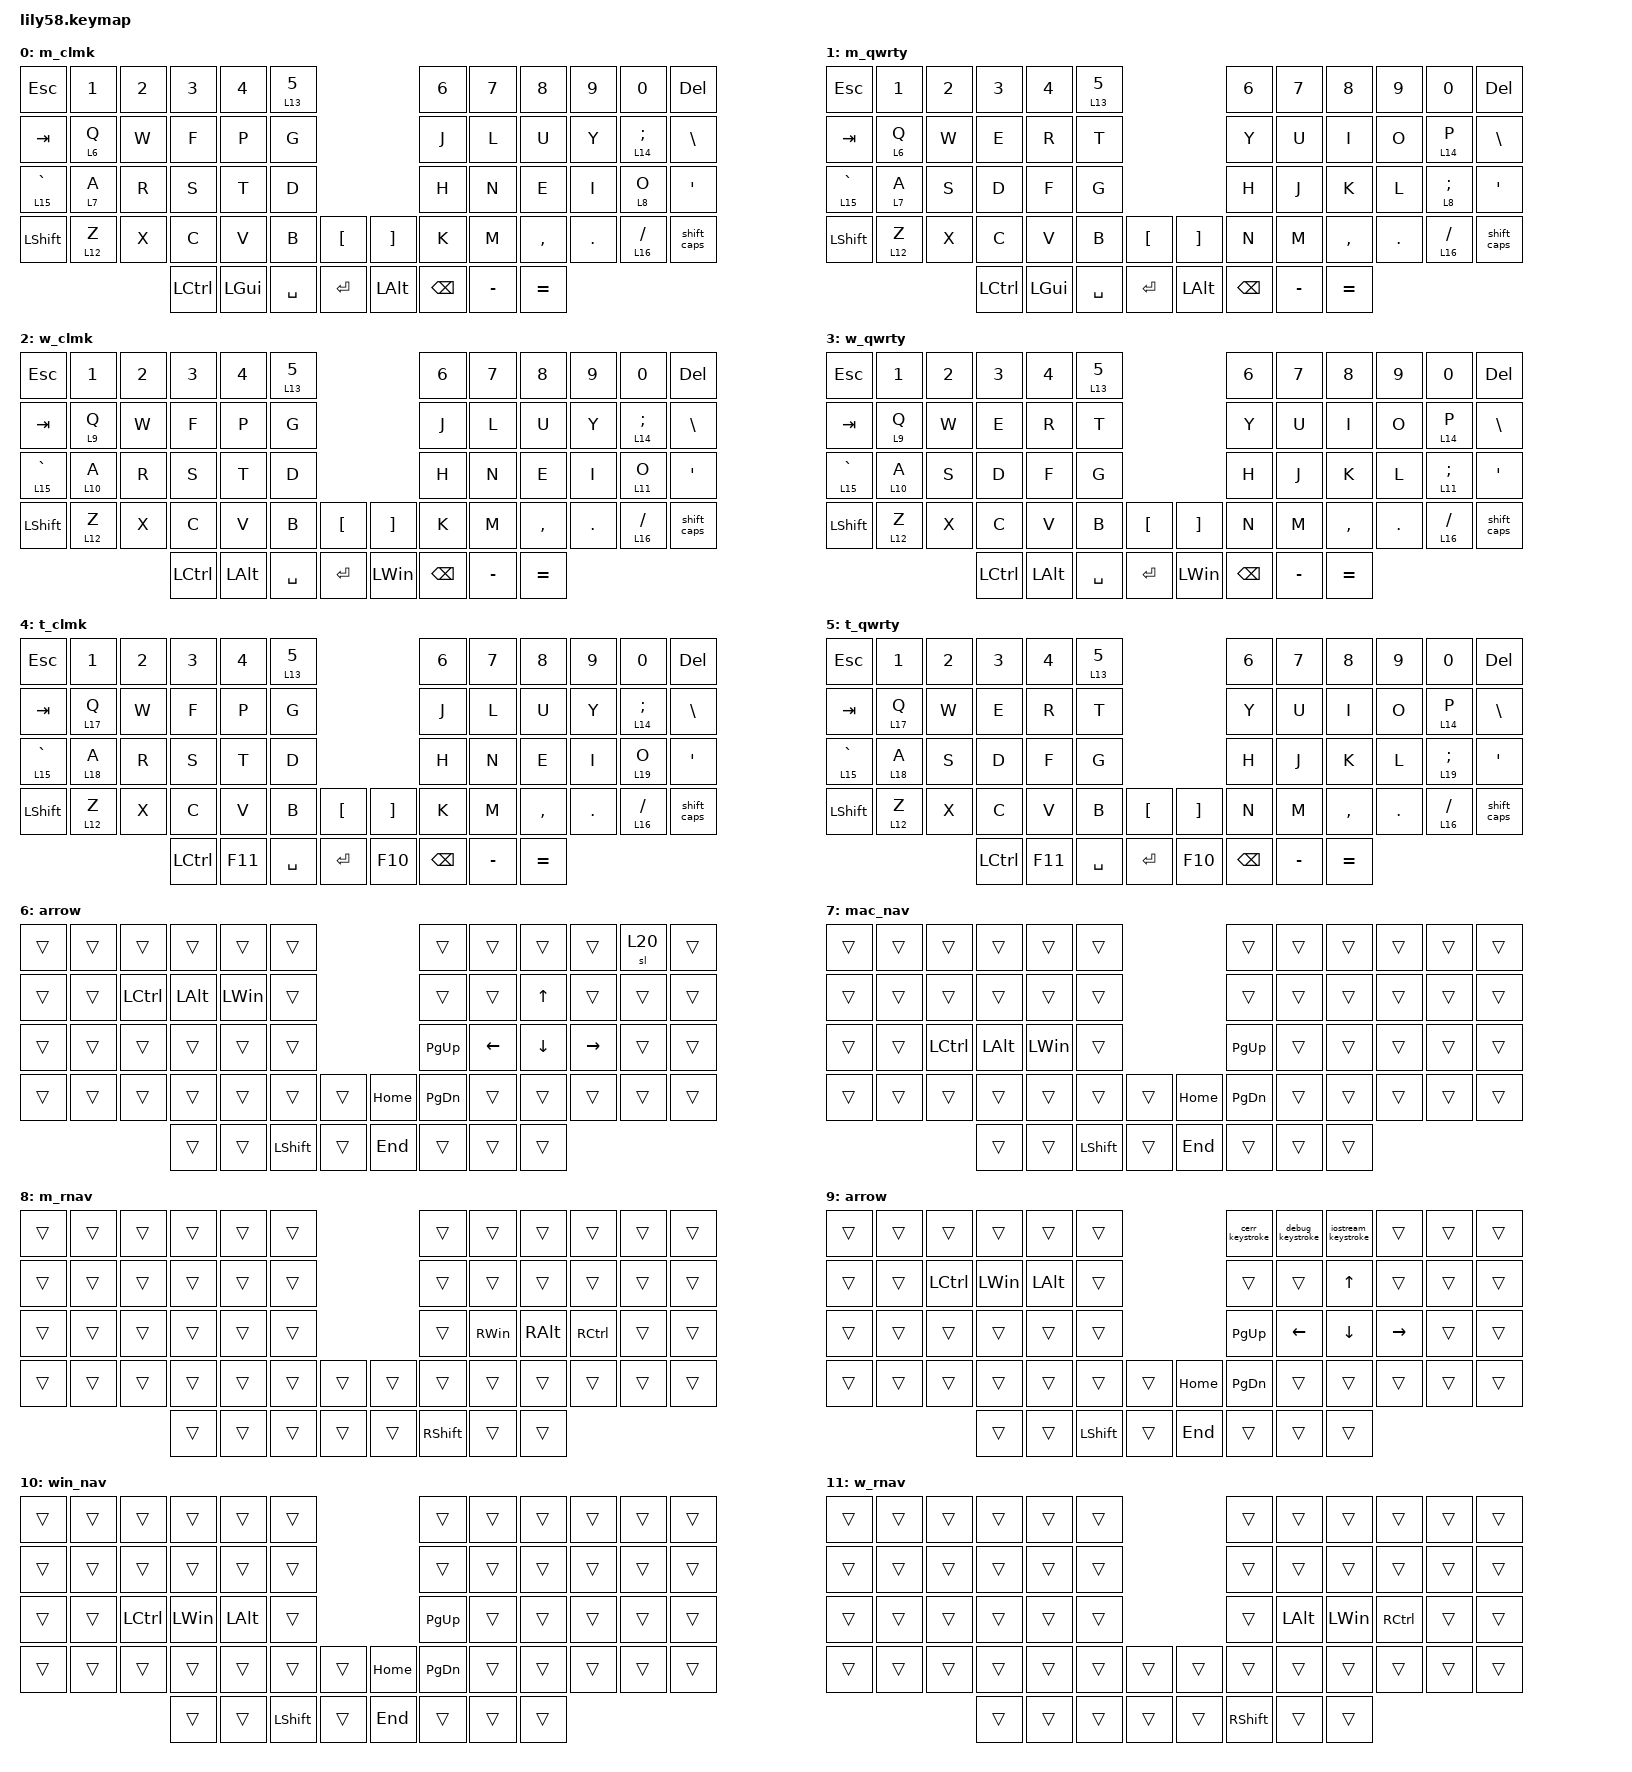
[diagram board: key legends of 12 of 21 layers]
#include <dt-bindings/zmk/mouse.h>
#include <behaviors.dtsi>
#include <dt-bindings/zmk/bt.h>
#include <dt-bindings/zmk/keys.h>
#include <dt-bindings/zmk/pointing.h>

&lt {
    flavor = "balanced";
    tapping-term-ms = <200>;
    quick-tap-ms = <165>;
    require-prior-idle-ms = <127>;
};

/ {
    macros {
        to_mac_qwerty: to_mac_qwerty {
            compatible = "zmk,behavior-macro";
            #binding-cells = <0>;
            bindings = <&to 1 &bt BT_SEL 0>;
            label = "TO_MAC_QWERTY";
        };

        to_win_qwerty: to_win_qwerty {
            compatible = "zmk,behavior-macro";
            #binding-cells = <0>;
            bindings = <&to 3 &bt BT_SEL 1>;
            label = "TO_WIN_QWERTY";
        };

        to_phone_qwerty: to_phone_qwerty {
            compatible = "zmk,behavior-macro";
            #binding-cells = <0>;
            bindings = <&to 5 &bt BT_SEL 2>;
            label = "TO_PHONE_QWERTY";
        };

        to_tablet_qwerty: to_tablet_qwerty {
            compatible = "zmk,behavior-macro";
            #binding-cells = <0>;
            bindings = <&to 5 &bt BT_SEL 3>;
            label = "TO_TABLET_QWERTY";
        };

        to_mac_colemak: to_mac_colemak {
            compatible = "zmk,behavior-macro";
            #binding-cells = <0>;
            bindings = <&to 0 &bt BT_SEL 0>;
            label = "TO_MAC_COLEMAC";
        };

        to_win_colemak: to_win_colemak {
            compatible = "zmk,behavior-macro";
            #binding-cells = <0>;
            bindings = <&to 2 &bt BT_SEL 1>;
            label = "TO_WIN_COLEMAK";
        };

        to_phone_colemak: to_phone_colemak {
            compatible = "zmk,behavior-macro";
            #binding-cells = <0>;
            bindings = <&to 4 &bt BT_SEL 2>;
            label = "TO_PHONE_COLEMAK";
        };

        to_tablet_colemak: to_tablet_colemak {
            compatible = "zmk,behavior-macro";
            #binding-cells = <0>;
            bindings = <&to 4 &bt BT_SEL 3>;
            label = "TO_TABLET_COLEMAK";
        };

        caps_long_press: caps_long_press {
            compatible = "zmk,behavior-macro";
            #binding-cells = <0>;
            tap-ms = <150>;
            bindings = <&kp CAPS>;
            label = "CAPS_LONG_PRESS";
        };

        cerr_keystroke: cerr_keystroke {
            compatible = "zmk,behavior-macro";
            #binding-cells = <0>;
            bindings =
                <&macro_tap_time 1>,
                <&none &kp S &kp T &kp D &kp COLON &kp COLON &kp C &kp E &kp R &kp R &kp SPACE &kp LT &kp LT &kp SPACE &kp SPACE &kp LT &kp LT &kp SPACE &kp S &kp T &kp D &kp LS(COLON) &kp LS(COLON) &kp E &kp N &kp D &kp L &kp SEMI &kp LC(LEFT) &kp LC(LEFT) &kp LC(LEFT) &kp LC(LEFT) &kp LEFT>;

            label = "CERR";
        };

        debug_keystroke: debug_keystroke {
            compatible = "zmk,behavior-macro";
            #binding-cells = <0>;
            bindings =
                <&macro_tap_time 1>,
                <&none &kp LS(R) &kp LS(A) &kp LS(I) &kp LS(L) &kp UNDER &kp LS(D) &kp LS(E) &kp LS(B) &kp LS(U) &kp LS(G) &kp LPAR &kp RPAR &kp SEMI &kp LEFT &kp LEFT>;

            label = "DEBUG";
        };

        iostream_keystroke: iostream_keystroke {
            compatible = "zmk,behavior-macro";
            #binding-cells = <0>;
            bindings =
                <&macro_tap_time 1>,
                <&none &kp POUND &kp I &kp N &kp C &kp L &kp U &kp D &kp E &kp SPACE &kp LT &kp I &kp O &kp S &kp T &kp R &kp E &kp A &kp M &kp GT &kp RET>;

            label = "IOSTREAM";
        };

        test_cmd: test_cmd {
            compatible = "zmk,behavior-macro";
            #binding-cells = <0>;
            bindings =
                <&macro_tap_time 1>,
                <&none &kp T &kp E &kp S &kp T &kp SPACE &kp T &kp H &kp I &kp S &kp SPACE &kp P &kp L &kp E &kp A &kp S &kp E &kp SPACE &kp T &kp E &kp S &kp T &kp SPACE &kp T &kp H &kp I &kp S &kp SPACE &kp R &kp D &kp U>;

            label = "TEST_CMD";
        };

        stay_awake: stay_awake {
            compatible = "zmk,behavior-macro";
            #binding-cells = <0>;
            bindings =
                <&macro_tap_time 1>,
                <&kp C &kp A &kp F &kp F &kp E &kp I &kp N &kp A &kp T &kp E &kp SPACE &kp MINUS &kp D>;

            label = "STAY_AWAKE";
        };

        llvm_errs: llvm_errs {
            compatible = "zmk,behavior-macro";
            #binding-cells = <0>;
            bindings =
                <&macro_tap_time 1>,
                <&none &kp L &kp L &kp V &kp M &kp COLON &kp COLON &kp E &kp R &kp R &kp S &kp LPAR &kp RPAR &kp SPACE &kp LT &kp LT &kp SPACE &kp SPACE &kp LT &kp LT &kp SPACE &kp DQT &kp BSLH &kp N &kp DQT &kp SEMI &kp LC(LEFT) &kp LC(LEFT) &kp LC(LEFT) &kp LC(LEFT) &kp LEFT>;

            label = "LLVM_ERRS";
        };

        sn_cl_very_verbose: sn_cl_very_verbose {
            compatible = "zmk,behavior-macro";
            #binding-cells = <0>;
            bindings =
                <&macro_tap_time 1>,
                <&none &kp S &kp N &kp COLON &kp COLON &kp C &kp L &kp UNDER &kp V &kp E &kp R &kp Y &kp UNDER &kp V &kp E &kp R &kp B &kp O &kp S &kp E &kp SPACE &kp EQUAL &kp SPACE &kp T &kp R &kp U &kp E &kp SEMI>;

            label = "SN_CL_VERY_VERBOSE";
        };

        tolanerhel: tolanerhel {
            compatible = "zmk,behavior-macro";
            #binding-cells = <0>;
            bindings =
                <&macro_tap_time 1>,
                <&none &kp T &kp O &kp L &kp A &kp N &kp E &kp R &kp H &kp E &kp L &kp SPACE>;

            label = "TOLANERHEL";
        };

        dockerssh2: dockerssh2 {
            compatible = "zmk,behavior-macro";
            #binding-cells = <0>;
            bindings =
                <&macro_tap_time 1>,
                <&none &kp B &kp A &kp S &kp H &kp SPACE &kp TILDE &kp FSLH &kp S &kp C &kp R &kp I &kp P &kp T &kp S &kp FSLH &kp D &kp O &kp C &kp K &kp E &kp R &kp UNDER &kp S &kp S &kp H &kp N2 &kp DOT &kp S &kp H &kp RET>;

            label = "DOCKERSSH2";
        };

        final_report: final_report {
            compatible = "zmk,behavior-macro";
            #binding-cells = <0>;
            bindings =
                <&macro_wait_time 1>,
                <&none &kp RG(R) &kp R &kp A &kp I &kp L &kp UNDER &kp G &kp E &kp N &kp RET &kp ENTER &kp RG(R) &kp R &kp E &kp P &kp O &kp R &kp T &kp S &kp RET &kp ENTER &kp RG(R) &kp LS(F) &kp I &kp N &kp A &kp L &kp DOT &kp R &kp E &kp P &kp O &kp R &kp T &kp RET &kp ENTER>;

            label = "FINAL_REPORT";
        };

        summary_report: summary_report {
            compatible = "zmk,behavior-macro";
            #binding-cells = <0>;
            bindings =
                <&macro_wait_time 1>,
                <&none &kp RG(R) &kp R &kp A &kp I &kp L &kp UNDER &kp G &kp E &kp N &kp RET &kp ENTER &kp RG(R) &kp R &kp E &kp P &kp O &kp R &kp T &kp S &kp RET &kp ENTER &kp RG(R) &kp LS(S) &kp U &kp M &kp M &kp A &kp R &kp Y &kp DOT &kp R &kp E &kp P &kp O &kp R &kp T &kp RET &kp ENTER>;

            label = "SUMMARY_REPORT";
        };
    };

    combos {
        compatible = "zmk,combos";

        combo_pgup {
            bindings = <&kp PG_UP>;
            key-positions = <30 18>;
        };

        combo_pgdn {
            bindings = <&kp PG_DN>;
            key-positions = <30 44>;
        };

        combo_home {
            bindings = <&kp HOME>;
            key-positions = <30 43>;
        };

        combo_end {
            bindings = <&kp END>;
            key-positions = <44 43>;
        };
    };

    behaviors {
        shift_caps: shift_caps {
            compatible = "zmk,behavior-tap-dance";
            label = "SHIFT_CAPS";
            #binding-cells = <0>;
            bindings = <&kp RSHIFT>, <&caps_long_press>;

            tapping-term-ms = <200>;
        };

        to_mac: to_mac {
            compatible = "zmk,behavior-tap-dance";
            label = "TO_MAC";
            #binding-cells = <0>;
            bindings = <&to_mac_colemak>, <&to_mac_qwerty>, <&bt BT_DISC 0>;
        };

        to_win: to_win {
            compatible = "zmk,behavior-tap-dance";
            label = "TO_WIN";
            #binding-cells = <0>;
            bindings = <&to_win_colemak>, <&to_win_qwerty>, <&bt BT_DISC 1>;
        };

        to_phone: to_phone {
            compatible = "zmk,behavior-tap-dance";
            label = "TO_PHONE";
            #binding-cells = <0>;
            bindings = <&to_phone_colemak>, <&to_phone_qwerty>, <&bt BT_DISC 2>;
        };

        to_tablet: to_tablet {
            compatible = "zmk,behavior-tap-dance";
            label = "TO_TABLET";
            #binding-cells = <0>;
            bindings =
                <&to_tablet_colemak>,
                <&to_tablet_qwerty>,
                <&bt BT_DISC 3>;
        };
    };

    keymap {
        compatible = "zmk,keymap";

        m_clmk {
            label = "m_clmk";
            bindings = <
&kp ESCAPE      &kp N1    &kp N2  &kp N3     &kp N4    &lt 13 N5                        &kp N6    &kp N7     &kp N8     &kp N9   &kp N0            &kp DEL
&kp TAB         &lt 6 Q   &kp W   &kp F      &kp P     &kp G                            &kp J     &kp L      &kp U      &kp Y    &lt 14 SEMICOLON  &kp BSLH
&lt 15 GRAVE    &lt 7 A   &kp R   &kp S      &kp T     &kp D                            &kp H     &kp N      &kp E      &kp I    &lt 8 O           &kp SQT
&kp LEFT_SHIFT  &lt 12 Z  &kp X   &kp C      &kp V     &kp B      &kp LBKT    &kp RBKT  &kp K     &kp M      &kp COMMA  &kp DOT  &lt 16 SLASH      &shift_caps
                                  &kp LCTRL  &kp LGUI  &kp SPACE  &kp RET     &kp LALT  &kp BSPC  &kp MINUS  &kp EQUAL
            >;
        };

        m_qwrty {
            display-name = "m_qwrty";
            bindings = <
&kp ESC       &kp N1    &kp N2  &kp N3     &kp N4    &lt 13 NUMBER_5                                         &kp N6         &kp N7     &kp N8     &kp N9   &kp N0           &kp DELETE
&kp TAB       &lt 6 Q   &kp W   &kp E      &kp R     &kp T                                                   &kp Y          &kp U      &kp I      &kp O    &lt 14 P         &kp BACKSLASH
&lt 15 GRAVE  &lt 7 A   &kp S   &kp D      &kp F     &kp G                                                   &kp H          &kp J      &kp K      &kp L    &lt 8 SEMICOLON  &kp SQT
&kp LSHIFT    &lt 12 Z  &kp X   &kp C      &kp V     &kp B            &kp LEFT_BRACKET    &kp RIGHT_BRACKET  &kp N          &kp M      &kp COMMA  &kp DOT  &lt 16 SLASH     &shift_caps
                                &kp LCTRL  &kp LGUI  &kp SPACE        &kp ENTER           &kp LEFT_ALT       &kp BACKSPACE  &kp MINUS  &kp EQUAL
            >;

            label = "mac_qwerty";
        };

        w_clmk {
            display-name = "w_clmk";
            bindings = <
&kp ESC       &kp N1    &kp N2  &kp N3     &kp N4        &lt 13 N5                            &kp N6    &kp N7     &kp N8     &kp N9   &kp N0            &kp DEL
&kp TAB       &lt 9 Q   &kp W   &kp F      &kp P         &kp G                                &kp J     &kp L      &kp U      &kp Y    &lt 14 SEMICOLON  &kp BSLH
&lt 15 GRAVE  &lt 10 A  &kp R   &kp S      &kp T         &kp D                                &kp H     &kp N      &kp E      &kp I    &lt 11 O          &kp SQT
&kp LSHFT     &lt 12 Z  &kp X   &kp C      &kp V         &kp B      &kp LBKT    &kp RBKT      &kp K     &kp M      &kp COMMA  &kp DOT  &lt 16 SLASH      &shift_caps
                                &kp LCTRL  &kp LEFT_ALT  &kp SPACE  &kp RET     &kp LEFT_WIN  &kp BSPC  &kp MINUS  &kp EQUAL
            >;

            label = "win_colemak";
        };

        w_qwrty {
            display-name = "w_qwrty";
            bindings = <
&kp ESC         &kp N1    &kp N2  &kp N3            &kp N4        &lt 13 N5                             &kp N6         &kp N7     &kp N8     &kp N9   &kp N0            &kp DEL
&kp TAB         &lt 9 Q   &kp W   &kp E             &kp R         &kp T                                 &kp Y          &kp U      &kp I      &kp O    &lt 14 P          &kp BSLH
&lt 15 GRAVE    &lt 10 A  &kp S   &kp D             &kp F         &kp G                                 &kp H          &kp J      &kp K      &kp L    &lt 11 SEMICOLON  &kp SQT
&kp LEFT_SHIFT  &lt 12 Z  &kp X   &kp C             &kp V         &kp B      &kp LBKT     &kp RBKT      &kp N          &kp M      &kp COMMA  &kp DOT  &lt 16 SLASH      &shift_caps
                                  &kp LEFT_CONTROL  &kp LEFT_ALT  &kp SPACE  &kp ENTER    &kp LEFT_WIN  &kp BACKSPACE  &kp MINUS  &kp EQUAL
            >;

            label = "win_qwerty";
        };

        t_clmk {
            label = "teamviewer_colemak";
            display-name = "t_clmk";
            bindings = <
&kp ESC       &kp N1    &kp N2  &kp N3     &kp N4   &lt 13 N5                        &kp N6    &kp N7     &kp N8     &kp N9   &kp N0            &kp DEL
&kp TAB       &lt 17 Q  &kp W   &kp F      &kp P    &kp G                            &kp J     &kp L      &kp U      &kp Y    &lt 14 SEMICOLON  &kp BSLH
&lt 15 GRAVE  &lt 18 A  &kp R   &kp S      &kp T    &kp D                            &kp H     &kp N      &kp E      &kp I    &lt 19 O          &kp SQT
&kp LSHFT     &lt 12 Z  &kp X   &kp C      &kp V    &kp B      &kp LBKT    &kp RBKT  &kp K     &kp M      &kp COMMA  &kp DOT  &lt 16 SLASH      &shift_caps
                                &kp LCTRL  &kp F11  &kp SPACE  &kp RET     &kp F10   &kp BSPC  &kp MINUS  &kp EQUAL
            >;
        };

        t_qwrty {
            label = "teamviewer_qwerty";
            display-name = "t_qwrty";
            bindings = <
&kp ESC         &kp N1    &kp N2  &kp N3            &kp N4   &lt 13 N5                         &kp N6         &kp N7     &kp N8     &kp N9   &kp N0            &kp DEL
&kp TAB         &lt 17 Q  &kp W   &kp E             &kp R    &kp T                             &kp Y          &kp U      &kp I      &kp O    &lt 14 P          &kp BSLH
&lt 15 GRAVE    &lt 18 A  &kp S   &kp D             &kp F    &kp G                             &kp H          &kp J      &kp K      &kp L    &lt 19 SEMICOLON  &kp SQT
&kp LEFT_SHIFT  &lt 12 Z  &kp X   &kp C             &kp V    &kp B      &kp LBKT     &kp RBKT  &kp N          &kp M      &kp COMMA  &kp DOT  &lt 16 SLASH      &shift_caps
                                  &kp LEFT_CONTROL  &kp F11  &kp SPACE  &kp ENTER    &kp F10   &kp BACKSPACE  &kp MINUS  &kp EQUAL
            >;
        };

        mac_arrows {
            display-name = "arrow";
            bindings = <
&trans  &trans  &trans     &trans        &trans        &trans                              &trans     &trans          &trans          &trans           &sl 20  &trans
&trans  &trans  &kp LCTRL  &kp LEFT_ALT  &kp LEFT_WIN  &trans                              &trans     &trans          &kp UP_ARROW    &trans           &trans  &trans
&trans  &trans  &trans     &trans        &trans        &trans                              &kp PG_UP  &kp LEFT_ARROW  &kp DOWN_ARROW  &kp RIGHT_ARROW  &trans  &trans
&trans  &trans  &trans     &trans        &trans        &trans          &trans    &kp HOME  &kp PG_DN  &trans          &trans          &trans           &trans  &trans
                           &trans        &trans        &kp LEFT_SHIFT  &trans    &kp END   &trans     &trans          &trans
            >;

            label = "m_arrow";
        };

        mac_nav {
            bindings = <
&trans  &trans  &trans     &trans        &trans        &trans                              &trans     &trans  &trans  &trans  &trans  &trans
&trans  &trans  &trans     &trans        &trans        &trans                              &trans     &trans  &trans  &trans  &trans  &trans
&trans  &trans  &kp LCTRL  &kp LEFT_ALT  &kp LEFT_WIN  &trans                              &kp PG_UP  &trans  &trans  &trans  &trans  &trans
&trans  &trans  &trans     &trans        &trans        &trans          &trans    &kp HOME  &kp PG_DN  &trans  &trans  &trans  &trans  &trans
                           &trans        &trans        &kp LEFT_SHIFT  &trans    &kp END   &trans     &trans  &trans
            >;

            label = "mac_nav";
        };

        mac_nav_rhs {
            bindings = <
&trans  &trans  &trans  &trans  &trans  &trans                    &trans           &trans         &trans         &trans     &trans  &trans
&trans  &trans  &trans  &trans  &trans  &trans                    &trans           &trans         &trans         &trans     &trans  &trans
&trans  &trans  &trans  &trans  &trans  &trans                    &trans           &kp RIGHT_WIN  &kp RIGHT_ALT  &kp RCTRL  &trans  &trans
&trans  &trans  &trans  &trans  &trans  &trans  &trans    &trans  &trans           &trans         &trans         &trans     &trans  &trans
                        &trans  &trans  &trans  &trans    &trans  &kp RIGHT_SHIFT  &trans         &trans
            >;

            label = "m_rnav";
        };

        windows_arrows {
            label = "arrow";
            display-name = "arrow";
            bindings = <
&trans  &trans  &trans     &trans        &trans        &trans                              &cerr_keystroke  &debug_keystroke  &iostream_keystroke  &trans           &trans  &trans
&trans  &trans  &kp LCTRL  &kp LEFT_WIN  &kp LEFT_ALT  &trans                              &trans           &trans            &kp UP_ARROW         &trans           &trans  &trans
&trans  &trans  &trans     &trans        &trans        &trans                              &kp PG_UP        &kp LEFT_ARROW    &kp DOWN_ARROW       &kp RIGHT_ARROW  &trans  &trans
&trans  &trans  &trans     &trans        &trans        &trans          &trans    &kp HOME  &kp PG_DN        &trans            &trans               &trans           &trans  &trans
                           &trans        &trans        &kp LEFT_SHIFT  &trans    &kp END   &trans           &trans            &trans
            >;

            sensor-bindings = <&inc_dec_kp C_VOL_UP C_VOL_DN>;
        };

        windows_nav {
            label = "win_nav";
            bindings = <
&trans  &trans  &trans     &trans        &trans        &trans                              &trans     &trans  &trans  &trans  &trans  &trans
&trans  &trans  &trans     &trans        &trans        &trans                              &trans     &trans  &trans  &trans  &trans  &trans
&trans  &trans  &kp LCTRL  &kp LEFT_WIN  &kp LEFT_ALT  &trans                              &kp PG_UP  &trans  &trans  &trans  &trans  &trans
&trans  &trans  &trans     &trans        &trans        &trans          &trans    &kp HOME  &kp PG_DN  &trans  &trans  &trans  &trans  &trans
                           &trans        &trans        &kp LEFT_SHIFT  &trans    &kp END   &trans     &trans  &trans
            >;
        };

        windows_nav_rhs {
            bindings = <
&trans  &trans  &trans  &trans  &trans  &trans                    &trans           &trans        &trans        &trans     &trans  &trans
&trans  &trans  &trans  &trans  &trans  &trans                    &trans           &trans        &trans        &trans     &trans  &trans
&trans  &trans  &trans  &trans  &trans  &trans                    &trans           &kp LEFT_ALT  &kp LEFT_WIN  &kp RCTRL  &trans  &trans
&trans  &trans  &trans  &trans  &trans  &trans  &trans    &trans  &trans           &trans        &trans        &trans     &trans  &trans
                        &trans  &trans  &trans  &trans    &trans  &kp RIGHT_SHIFT  &trans        &trans
            >;

            label = "w_rnav";
        };

        numpad {
            display-name = "num";
            bindings = <
&to_mac    &kp F1   &kp F2   &kp F3   &kp F4   &kp F5                         &kp F6  &kp F7        &kp F8        &kp F9        &kp F10  &kp F11
&to_win    &kp F15  &kp F16  &kp F17  &kp F18  &kp F19                        &trans  &kp NUMBER_7  &kp NUMBER_8  &kp NUMBER_9  &trans   &kp F12
&to_phone  &kp F20  &kp F21  &kp F22  &kp F23  &kp F24                        &trans  &kp NUMBER_4  &kp NUMBER_5  &kp NUMBER_6  &trans   &kp F13
&trans     &trans   &trans   &trans   &trans   &trans   &to_tablet    &trans  &trans  &kp NUMBER_1  &kp NUMBER_2  &kp NUMBER_3  &trans   &kp F14
                             &trans   &trans   &trans   &trans        &trans  &trans  &kp NUMBER_0  &trans
            >;

            label = "numpad";
        };

        media {
            bindings = <
&trans  &trans  &trans  &trans  &trans  &trans                               &trans            &trans        &trans              &trans  &trans  &trans
&trans  &trans  &trans  &trans  &trans  &trans                               &trans            &trans        &trans              &trans  &trans  &trans
&trans  &trans  &trans  &trans  &trans  &trans                               &trans            &trans        &trans              &trans  &trans  &trans
&trans  &trans  &trans  &trans  &trans  &trans  &trans    &kp C_VOLUME_UP    &kp C_MUTE        &trans        &trans              &trans  &trans  &trans
                        &trans  &trans  &trans  &trans    &kp C_VOLUME_DOWN  &kp C_PLAY_PAUSE  &kp C_REWIND  &kp C_FAST_FORWARD
            >;

            label = "media";
        };

        mouse {
            bindings = <
&trans  &trans  &trans          &trans          &trans           &trans                          &trans  &trans  &trans  &trans  &trans  &trans
&trans  &trans  &trans          &mmv MOVE_UP    &trans           &trans                          &trans  &trans  &trans  &trans  &trans  &trans
&trans  &trans  &mmv MOVE_LEFT  &mmv MOVE_DOWN  &mmv MOVE_RIGHT  &trans                          &trans  &trans  &trans  &trans  &trans  &trans
&trans  &trans  &trans          &trans          &trans           &trans     &trans       &trans  &trans  &trans  &trans  &trans  &trans  &trans
                                &msc SCRL_DOWN  &msc SCRL_UP     &mkp LCLK  &mkp RCLK    &trans  &trans  &trans  &trans
            >;

            label = "mouse";
        };

        left_mouse {
            bindings = <
&trans  &trans          &trans          &trans           &trans        &trans                          &trans  &trans  &trans  &trans  &trans  &trans
&trans  &trans          &mmv MOVE_UP    &trans           &trans        &trans                          &trans  &trans  &trans  &trans  &trans  &trans
&trans  &mmv MOVE_LEFT  &mmv MOVE_DOWN  &mmv MOVE_RIGHT  &trans        &trans                          &trans  &trans  &trans  &trans  &trans  &trans
&trans  &kp N6          &kp N7          &kp N8           &kp N9        &kp N0     &trans       &trans  &trans  &trans  &trans  &trans  &trans  &trans
                                        &msc SCRL_DOWN   &msc SCRL_UP  &mkp LCLK  &mkp RCLK    &trans  &trans  &trans  &trans
            >;

            label = "left_mouse";
        };

        switch_layer {
            display-name = "lyr_swp";
            bindings = <
&trans  &trans  &trans  &trans  &trans  &trans                                &bt BT_CLR  &trans  &trans  &trans  &trans  &to_mac
&trans  &trans  &trans  &trans  &trans  &trans                                &trans      &trans  &trans  &trans  &trans  &to_win
&trans  &trans  &trans  &trans  &trans  &trans                                &trans      &trans  &trans  &trans  &trans  &to_phone
&trans  &trans  &trans  &trans  &trans  &trans      &trans        &to_tablet  &trans      &trans  &trans  &trans  &trans  &kp F14
                        &trans  &trans  &bt BT_PRV  &bt BT_NXT    &trans      &trans      &trans  &trans
            >;
        };

        T_arrows {
            label = "teamviewer_arrows";
            display-name = "arrow";
            bindings = <
&trans  &trans  &trans     &trans   &trans   &trans                              &cerr_keystroke  &debug_keystroke  &iostream_keystroke  &trans           &trans  &trans
&trans  &trans  &kp LCTRL  &kp F10  &kp F11  &trans                              &trans           &trans            &kp UP_ARROW         &trans           &trans  &trans
&trans  &trans  &trans     &trans   &trans   &trans                              &kp PG_UP        &kp LEFT_ARROW    &kp DOWN_ARROW       &kp RIGHT_ARROW  &trans  &trans
&trans  &trans  &trans     &trans   &trans   &trans          &trans    &kp HOME  &kp PG_DN        &trans            &trans               &trans           &trans  &trans
                           &trans   &trans   &kp LEFT_SHIFT  &trans    &kp END   &trans           &trans            &trans
            >;

            sensor-bindings = <&inc_dec_kp C_VOL_UP C_VOL_DN>;
        };

        T_nav {
            label = "teamviewer_nav";
            bindings = <
&trans  &trans  &trans     &trans   &trans   &trans                              &trans     &trans  &trans  &trans  &trans  &trans
&trans  &trans  &trans     &trans   &trans   &trans                              &trans     &trans  &trans  &trans  &trans  &trans
&trans  &trans  &kp LCTRL  &kp F10  &kp F11  &trans                              &kp PG_UP  &trans  &trans  &trans  &trans  &trans
&trans  &trans  &trans     &trans   &trans   &trans          &trans    &kp HOME  &kp PG_DN  &trans  &trans  &trans  &trans  &trans
                           &trans   &trans   &kp LEFT_SHIFT  &trans    &kp END   &trans     &trans  &trans
            >;
        };

        T_rnav {
            label = "teamviewer_rnav";
            bindings = <
&trans  &trans  &trans  &trans  &trans  &trans                    &trans           &trans   &trans   &trans     &trans  &trans
&trans  &trans  &trans  &trans  &trans  &trans                    &trans           &trans   &trans   &trans     &trans  &trans
&trans  &trans  &trans  &trans  &trans  &trans                    &trans           &kp F11  &kp F10  &kp RCTRL  &trans  &trans
&trans  &trans  &trans  &trans  &trans  &trans  &trans    &trans  &trans           &trans   &trans   &trans     &trans  &trans
                        &trans  &trans  &trans  &trans    &trans  &kp RIGHT_SHIFT  &trans   &trans
            >;
        };

        macros {
            bindings = <
&trans  &trans  &trans            &trans           &trans               &trans                         &trans  &trans      &trans           &trans               &trans       &trans
&trans  &trans  &trans            &final_report    &trans               &trans                         &trans  &llvm_errs  &summary_report  &trans               &trans       &trans
&trans  &trans  &debug_keystroke  &cerr_keystroke  &test_cmd            &dockerssh2                    &trans  &trans      &trans           &iostream_keystroke  &tolanerhel  &trans
&trans  &trans  &trans            &stay_awake      &sn_cl_very_verbose  &trans       &trans    &trans  &trans  &trans      &trans           &trans               &trans       &trans
                                  &trans           &trans               &trans       &trans    &trans  &trans  &trans      &trans
            >;
        };
    };
};
